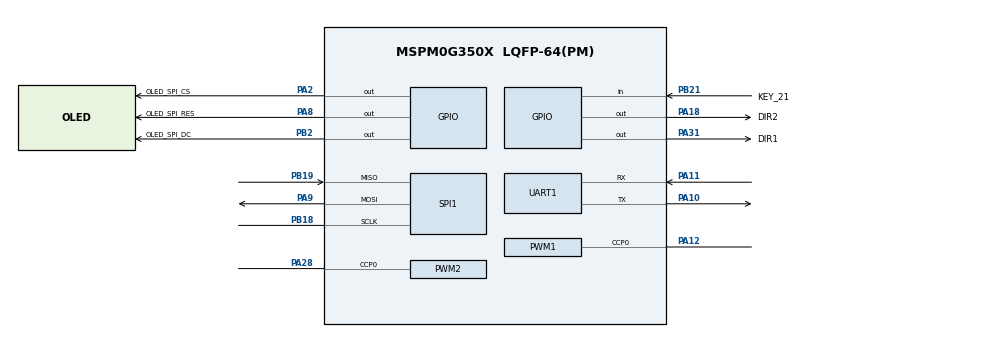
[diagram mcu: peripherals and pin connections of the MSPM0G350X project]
/**
 * @cliArgs --device "MSPM0G350X" --part "Default" --package "LQFP-64(PM)" --product "mspm0_sdk@2.10.00.04"
 * @versions {"tool":"1.26.2+4477"}
 */

/**
 * Import the modules used in this configuration.
 */
const GPIO   = scripting.addModule("/ti/driverlib/GPIO", {}, false);
const GPIO1  = GPIO.addInstance();
const GPIO2  = GPIO.addInstance();
const GPIO3  = GPIO.addInstance();
const GPIO4  = GPIO.addInstance();
const PWM    = scripting.addModule("/ti/driverlib/PWM", {}, false);
const PWM1   = PWM.addInstance();
const PWM2   = PWM.addInstance();
const SPI    = scripting.addModule("/ti/driverlib/SPI", {}, false);
const SPI1   = SPI.addInstance();
const SYSCTL = scripting.addModule("/ti/driverlib/SYSCTL");
const UART   = scripting.addModule("/ti/driverlib/UART", {}, false);
const UART1  = UART.addInstance();
const UART2  = UART.addInstance();

/**
 * Write custom configuration values to the imported modules.
 */
const divider9       = system.clockTree["UDIV"];
divider9.divideValue = 2;

const multiplier2         = system.clockTree["PLL_QDIV"];
multiplier2.multiplyValue = 5;

const mux4       = system.clockTree["EXHFMUX"];
mux4.inputSelect = "EXHFMUX_XTAL";

const mux8       = system.clockTree["HSCLKMUX"];
mux8.inputSelect = "HSCLKMUX_SYSPLL0";

const pinFunction4     = system.clockTree["HFXT"];
pinFunction4.inputFreq = 40;
pinFunction4.enable    = true;

GPIO1.$name                         = "OLED_SPI";
GPIO1.associatedPins.create(3);
GPIO1.associatedPins[0].$name       = "OLED_SPI_RES";
GPIO1.associatedPins[0].pin.$assign = "PA8";
GPIO1.associatedPins[1].$name       = "OLED_SPI_DC";
GPIO1.associatedPins[1].pin.$assign = "PB2";
GPIO1.associatedPins[2].$name       = "OLED_SPI_CS";
GPIO1.associatedPins[2].pin.$assign = "PA2";

const Board = scripting.addModule("/ti/driverlib/Board", {}, false);

GPIO2.$name                   = "RAZER";
GPIO2.associatedPins[0].$name = "RAZER_PIN";

GPIO3.$name                              = "KEY";
GPIO3.associatedPins[0].direction        = "INPUT";
GPIO3.associatedPins[0].internalResistor = "PULL_DOWN";
GPIO3.associatedPins[0].$name            = "KEY_21";
GPIO3.associatedPins[0].interruptEn      = true;
GPIO3.associatedPins[0].polarity         = "RISE_FALL";
GPIO3.associatedPins[0].pin.$assign      = "PB21";

GPIO4.$name                         = "STEP_MOTOR";
GPIO4.associatedPins.create(4);
GPIO4.associatedPins[0].$name       = "DIR2";
GPIO4.associatedPins[0].pin.$assign = "PA18";
GPIO4.associatedPins[1].$name       = "EN2";
GPIO4.associatedPins[2].$name       = "DIR1";
GPIO4.associatedPins[2].pin.$assign = "PA31";
GPIO4.associatedPins[3].$name       = "EN1";

PWM1.ccIndex                            = [0];
PWM1.clockDivider                       = 8;
PWM1.timerCount                         = 10000;
PWM1.pwmMode                            = "EDGE_ALIGN_UP";
PWM1.interrupts                         = ["LOAD_EVENT"];
PWM1.$name                              = "PWM2";
PWM1.PWM_CHANNEL_0.$name                = "ti_driverlib_pwm_PWMTimerCC0";
PWM1.PWM_CHANNEL_0.ccValue              = 5000;
PWM1.PWM_CHANNEL_0.dutyCycle            = 50;
PWM1.ccp0PinConfig.direction            = scripting.forceWrite("OUTPUT");
PWM1.ccp0PinConfig.hideOutputInversion  = scripting.forceWrite(false);
PWM1.ccp0PinConfig.onlyInternalResistor = scripting.forceWrite(false);
PWM1.ccp0PinConfig.passedPeripheralType = scripting.forceWrite("Digital");
PWM1.ccp0PinConfig.$name                = "ti_driverlib_gpio_GPIOPinGeneric3";
PWM1.peripheral.$assign                 = "TIMG0";
PWM1.peripheral.ccp0Pin.$assign         = "PA12";

PWM2.ccIndex                            = [0];
PWM2.interrupts                         = ["LOAD_EVENT"];
PWM2.clockDivider                       = 8;
PWM2.clockPrescale                      = 2;
PWM2.timerCount                         = 10000;
PWM2.pwmMode                            = "EDGE_ALIGN_UP";
PWM2.$name                              = "PWM1";
PWM2.PWM_CHANNEL_0.$name                = "ti_driverlib_pwm_PWMTimerCC1";
PWM2.PWM_CHANNEL_0.ccValue              = 5000;
PWM2.PWM_CHANNEL_0.dutyCycle            = 50;
PWM2.ccp0PinConfig.direction            = scripting.forceWrite("OUTPUT");
PWM2.ccp0PinConfig.hideOutputInversion  = scripting.forceWrite(false);
PWM2.ccp0PinConfig.onlyInternalResistor = scripting.forceWrite(false);
PWM2.ccp0PinConfig.passedPeripheralType = scripting.forceWrite("Digital");
PWM2.ccp0PinConfig.$name                = "ti_driverlib_gpio_GPIOPinGeneric4";
PWM2.peripheral.$assign                 = "TIMA1";
PWM2.peripheral.ccp0Pin.$assign         = "PA28";

SPI1.$name                      = "SPI_0";
SPI1.targetBitRate              = 1000000;
SPI1.frameFormat                = "MOTO3";
SPI1.sclkPinConfig.$name        = "ti_driverlib_gpio_GPIOPinGeneric0";
SPI1.mosiPinConfig.$name        = "ti_driverlib_gpio_GPIOPinGeneric1";
SPI1.misoPinConfig.$name        = "ti_driverlib_gpio_GPIOPinGeneric2";
SPI1.peripheral.$assign         = "SPI0";
SPI1.peripheral.sclkPin.$assign = "PB18";
SPI1.peripheral.mosiPin.$assign = "PA9";
SPI1.peripheral.misoPin.$assign = "PB19";

SYSCTL.forceDefaultClkConfig = true;
SYSCTL.clockTreeEn           = true;

UART1.$name                    = "UART_0";
UART1.targetBaudRate           = 115200;
UART1.enabledInterrupts        = ["RX"];
UART1.peripheral.rxPin.$assign = "PA11";
UART1.peripheral.txPin.$assign = "PA10";
UART1.txPinConfig.$name        = "ti_driverlib_gpio_GPIOPinGeneric5";
UART1.rxPinConfig.$name        = "ti_driverlib_gpio_GPIOPinGeneric6";

UART2.$name             = "UART_1";
UART2.targetBaudRate    = 115200;
UART2.txPinConfig.$name = "ti_driverlib_gpio_GPIOPinGeneric7";
UART2.rxPinConfig.$name = "ti_driverlib_gpio_GPIOPinGeneric8";

/**
 * Pinmux solution for unlocked pins/peripherals. This ensures that minor changes to the automatic solver in a future
 * version of the tool will not impact the pinmux you originally saw.  These lines can be completely deleted in order to
 * re-solve from scratch.
 */
pinFunction4.peripheral.$suggestSolution           = "SYSCTL";
pinFunction4.peripheral.hfxInPin.$suggestSolution  = "PA5";
pinFunction4.peripheral.hfxOutPin.$suggestSolution = "PA6";
Board.peripheral.$suggestSolution                  = "DEBUGSS";
Board.peripheral.swclkPin.$suggestSolution         = "PA20";
Board.peripheral.swdioPin.$suggestSolution         = "PA19";
GPIO2.associatedPins[0].pin.$suggestSolution       = "PB13";
GPIO4.associatedPins[1].pin.$suggestSolution       = "PB14";
GPIO4.associatedPins[3].pin.$suggestSolution       = "PB15";
UART1.peripheral.$suggestSolution                  = "UART0";
UART2.peripheral.$suggestSolution                  = "UART1";
UART2.peripheral.rxPin.$suggestSolution            = "PB5";
UART2.peripheral.txPin.$suggestSolution            = "PA17";
